# STTEST register map
Vendor: Texas Instruments
Peripheral module from a debugger description file (folder cc2538).
Registers are 32-bit, access per field, no defined reset value unless marked. A register's access mark holds for its fields unless they carry their own. Offsets are as the file gives them; lines under a group give offsets from that group; [hi:lo] are bit positions; {n}, {i} and the like mark numbered series; 'fields as' and 'values as' point back to an identical list; <NAME> marks a mode.

## STTEST — Register fields should be considered static unless otherwise noted as dynamic.
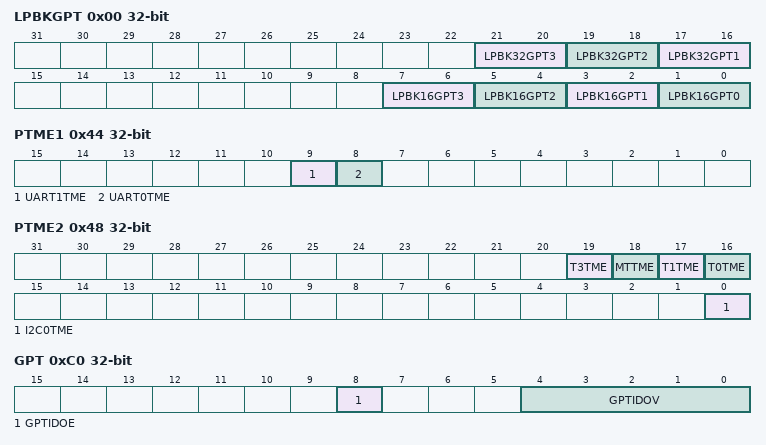
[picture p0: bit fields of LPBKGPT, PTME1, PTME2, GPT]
0x00 LPBKGPT — GPTIMER Internal loopback
  [21:20] LPBK32GPT3 rw — GPTimer3 32-bit RTC loopback modes 00: Normal operation 01: GPT0 GPTimerA PWM connected to GPT3 capture 10: GPT0 capture connected to GPT3 PWM GPTimer A 11: Reserved, defaults to normal operation
  [19:18] LPBK32GPT2 rw — GPTimer2 32-bit RTC loopback modes 00: Normal operation 01: GPT0 Timer A PWM connected to GPT2 capture 10: GPT0 capture connected to GPT2 PWM Timer A 11: Reserved, defaults to normal operation
  [17:16] LPBK32GPT1 rw — GPTimer1 32-bit RTC loopback modes 00: Normal operation 01: GPT0 timerA PWM connected to GPT1 capture 10: GPT0 capture connected to GPT1 PWM Timer A 11: Reserved, defaults to normal operation
  [2n+1:2n] LPBK16GPT{n} rw (n=0..3) — GPTimer{n} 16-bit loopback modes 00: Normal operation 01: Timer A PWM connected to Timer B capture 10: Timer A capture connected to Timer B PWM 11: Reserved, defaults to normal operation
0x04 LPBKUART — UART internal loopback
  [0] LPBKUART rw — UART0/1 loopback mode 0: Normal operation 1: UART0 TX (RX) connected to UART1 RX (TX)
0x0C LPBKI2C — I2C internal loopback
  [0] LPBKI2C rw — I2C0 Master/slave loopback mode 0: Normal mode
0x44 PTME1 — Peripheral test mode enable 1
  [9] UART1TME rw — UART1 test mode enable
  [8] UART0TME rw — UART0 test mode enable
0x48 PTME2 — Peripheral test mode enable 2
  [19] T3TME rw — Timer3 test mode enable
  [18] MTTME rw — MacTimer test mode enable
  [17] T1TME rw — Timer1 test mode enable
  [16] T0TME rw — Timer0 test mode enable
  [0] I2C0TME rw — I2C 0 test mode enable
0xC0 GPT — GPTIMER override values
  [8] GPTIDOE rw — GPTimer increment/decrement override enable
  [4:0] GPTIDOV rw — GPTimer increment/decrement override value
